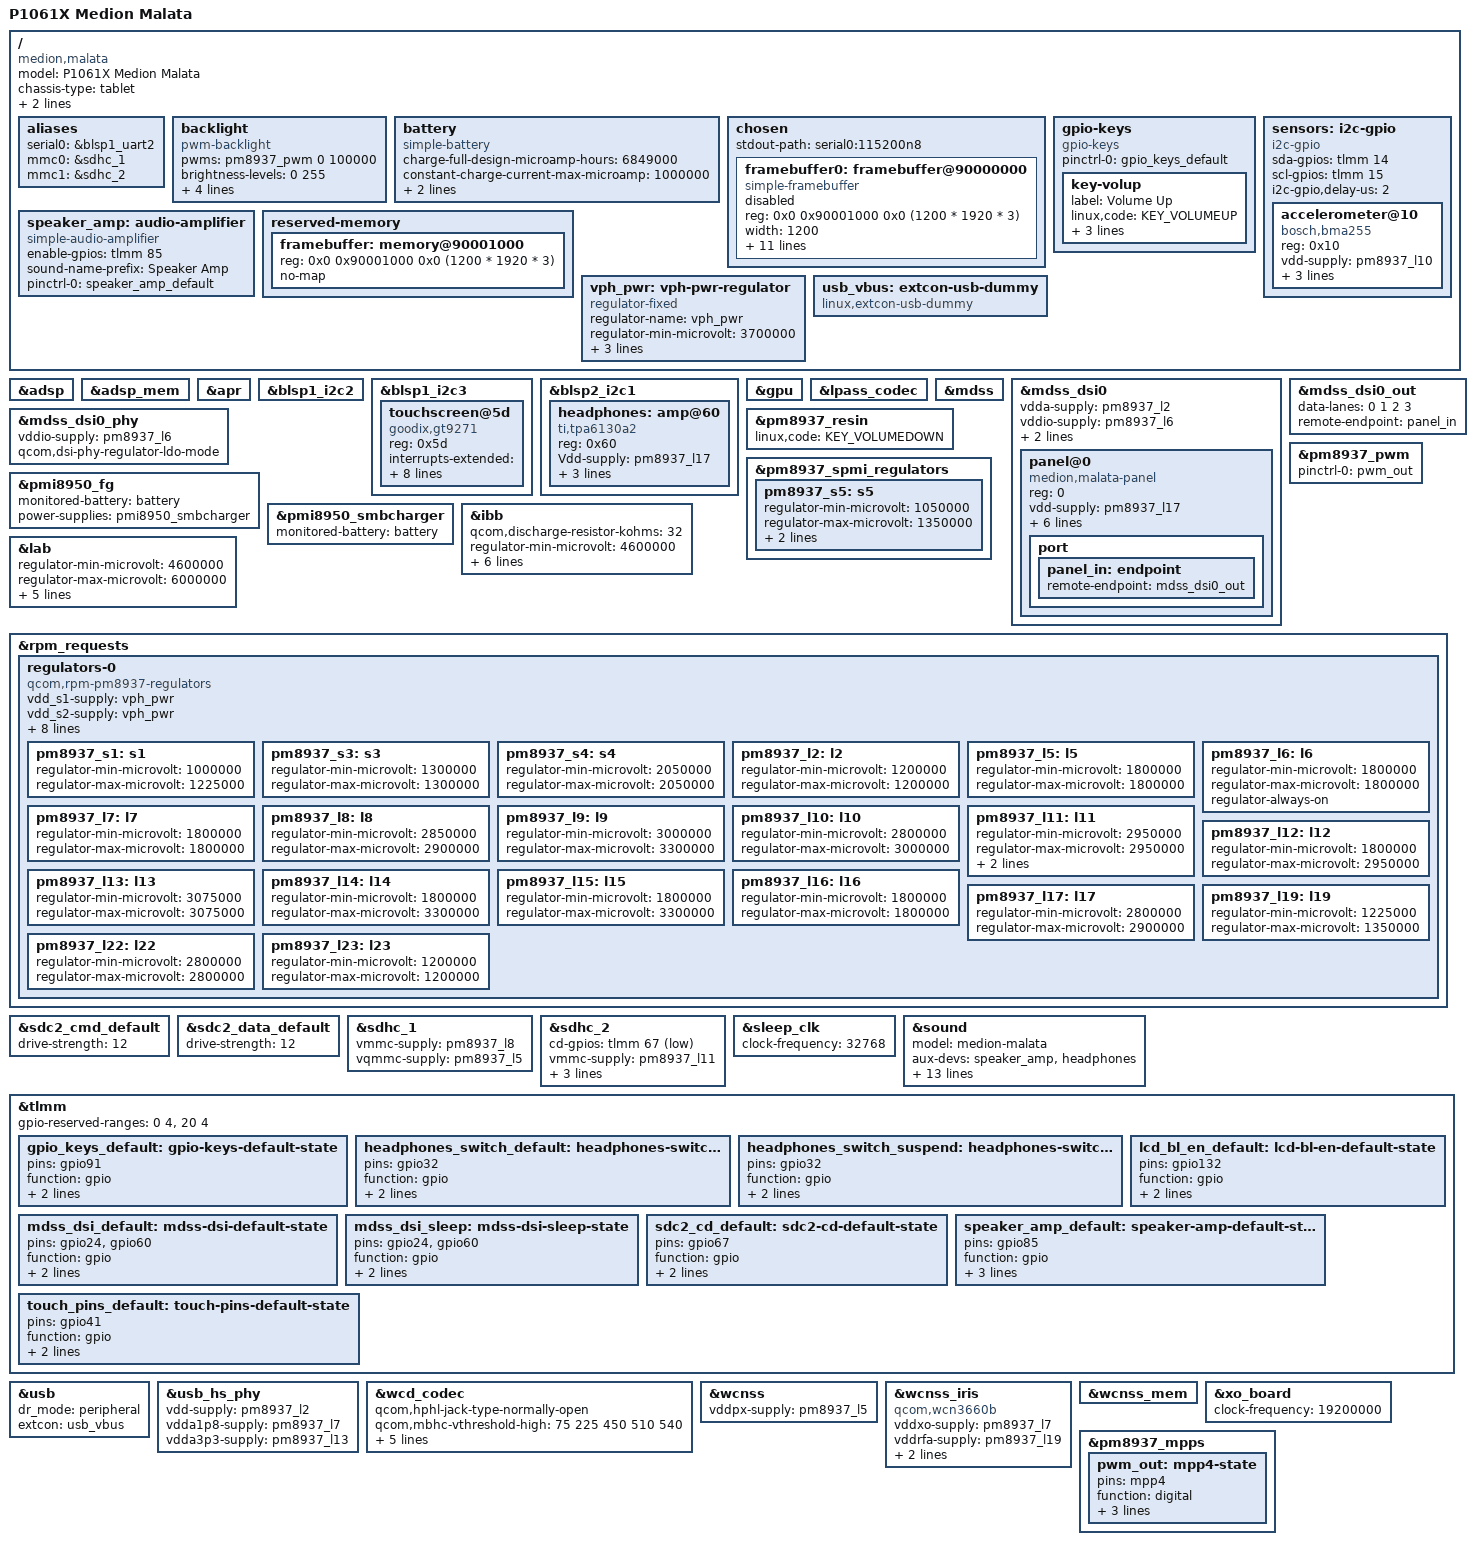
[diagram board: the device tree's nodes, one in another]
// SPDX-License-Identifier: BSD-3-Clause

/dts-v1/;

#include <dt-bindings/arm/qcom,ids.h>
#include <dt-bindings/gpio/gpio.h>
#include <dt-bindings/interrupt-controller/irq.h>
#include <dt-bindings/leds/common.h>
#include <dt-bindings/pinctrl/qcom,pmic-mpp.h>

#include "msm8937.dtsi"
#include "pm8937.dtsi"
#include "pmi8950.dtsi"
#include "msm8937-qdsp6.dtsi"

/ {
	model = "P1061X Medion Malata";
	compatible = "medion,malata", "qcom,msm8937";
	chassis-type = "tablet";

	qcom,msm-id = <QCOM_ID_MSM8937 0x0>;
	qcom,board-id = <QCOM_BOARD_ID_QRD 0x00>;

	aliases {
		serial0 = &blsp1_uart2;
		mmc0 = &sdhc_1;
		mmc1 = &sdhc_2;
	};

	backlight: backlight {
		compatible = "pwm-backlight";
		pwms = <&pm8937_pwm 0 100000>;

		brightness-levels = <0 255>;
		num-interpolated-steps = <255>;
		default-brightness-level = <128>;
		enable-gpios = <&tlmm 132 GPIO_ACTIVE_HIGH>;

		pinctrl-0 = <&lcd_bl_en_default>;
		pinctrl-names = "default";
	};

	battery: battery {
		compatible = "simple-battery";
 //TODO noch nicht komplett
		charge-full-design-microamp-hours = <6849000>;
		constant-charge-current-max-microamp = <1000000>;
		voltage-min-design-microvolt = <3400000>;
		voltage-max-design-microvolt = <4300000>;
	};

	chosen {
		#address-cells = <2>;
		#size-cells = <2>;
		ranges;
		stdout-path = "serial0:115200n8";
		//stdout-path = "framebuffer0";

		framebuffer0: framebuffer@90000000 {
			compatible = "simple-framebuffer";
			reg = <0x0 0x90001000 0x0 (1200 * 1920 * 3)>;
			width = <1200>;
			height = <1920>;
			stride = <(1200 * 3)>;
			format = "r8g8b8";

			clocks = <&gcc GCC_MDSS_AHB_CLK>,
				 <&gcc GCC_MDSS_AXI_CLK>,
				 <&gcc GCC_MDSS_VSYNC_CLK>,
				 <&gcc GCC_MDSS_MDP_CLK>,
				 <&gcc GCC_MDSS_BYTE0_CLK>,
				 <&gcc GCC_MDSS_PCLK0_CLK>,
				 <&gcc GCC_MDSS_ESC0_CLK>;
			power-domains = <&gcc MDSS_GDSC>;
			status = "disabled";
		};
	};

	gpio-keys {
		compatible = "gpio-keys";

		pinctrl-0 = <&gpio_keys_default>;
		pinctrl-names = "default";

		key-volup {
			label = "Volume Up";
			linux,code = <KEY_VOLUMEUP>;
			gpios = <&tlmm 91 GPIO_ACTIVE_LOW>,<&tlmm 127 GPIO_ACTIVE_LOW>,<&tlmm 128 GPIO_ACTIVE_LOW> ;
			debounce-interval = <15>;
		};
	};

	sensors: i2c-gpio {
		// i2c4 is protected, bitbanging
		compatible = "i2c-gpio";
		sda-gpios = <&tlmm 14 (GPIO_ACTIVE_HIGH|GPIO_OPEN_DRAIN)>;
		scl-gpios = <&tlmm 15 (GPIO_ACTIVE_HIGH|GPIO_OPEN_DRAIN)>;
		i2c-gpio,delay-us = <2>;        /* ~100 kHz */
		#address-cells = <1>;
		#size-cells = <0>;

		accelerometer@10 {
			compatible = "bosch,bma255";
			reg = <0x10>;

			vdd-supply = <&pm8937_l10>;
			vddio-supply = <&pm8937_l6>;

			interrupts-extended = <&tlmm 42 IRQ_TYPE_EDGE_RISING>;

			/*mount-matrix =	"0", "-1", "0",
					"1", "0", "0",
					"0", "0", "1";*/
		};
	};

	speaker_amp: audio-amplifier {
		compatible = "simple-audio-amplifier";
		enable-gpios = <&tlmm 85 GPIO_ACTIVE_HIGH>;
		sound-name-prefix = "Speaker Amp";
		pinctrl-0 = <&speaker_amp_default>;
		pinctrl-names = "default";
	};

	reserved-memory {
		framebuffer: memory@90001000 {
			//reg = <0x00 0x90001000 0x00 0x1400000>;
			reg = <0x0 0x90001000 0x0 (1200 * 1920 * 3)>;
			no-map;
		};

	/*	ramoops: ramoops@9ff00000 {
			compatible = "ramoops";
			reg = <0 0x9ff00000 0 0x100000>;

			record-size = <0x1000>;
			console-size = <0x40000>;
			ftrace-size = <0x1000>;
			pmsg-size = <0x20000>;
		};*/
	};

	vph_pwr: vph-pwr-regulator {
		compatible = "regulator-fixed";
		regulator-name = "vph_pwr";
		regulator-min-microvolt = <3700000>;
		regulator-max-microvolt = <3700000>;
		regulator-always-on;
		regulator-boot-on;
	};

	usb_vbus: extcon-usb-dummy {
		compatible = "linux,extcon-usb-dummy";
	};

	/*
	 * Until we hook up type-c detection, we
	 * have to stick with this. But it works.
	 
	usb_id: usb-id {
		compatible = "linux,extcon-usb-gpio";
		id-gpios = <&tlmm 97 GPIO_ACTIVE_HIGH>;
		pinctrl-names = "default";
		pinctrl-0 = <&usb_id_default>;
	};*/
};

&adsp {
	status = "okay";
};

&adsp_mem {
	status = "okay";
};

&apr {
	status = "okay";
};

&blsp1_i2c2 {
	status = "okay";

//TODO get it work
/*	typec_pd: usb-pd@3d {
		compatible = "pericom,pi3usb102", "gpio-sbu-mux";
		reg = <0x3d>;
*/
		/*interrupt-parent = <&tlmm>;
		interrupts = <97 IRQ_TYPE_LEVEL_LOW>;
		interrupt-names = "irq";*/

/*		pinctrl-names = "default";
		pinctrl-0 = <&pinctrl_typec>;
		vcc-supply = <&pm8937_l5>;
		select-gpios = <&tlmm  97 GPIO_ACTIVE_HIGH>;
		enable-gpios = <&tlmm 131 GPIO_ACTIVE_LOW>;
		mode-switch;
		orientation-switch;

		typec_con: connector {
			compatible = "usb-c-connector";
			label = "USB-C";

			port {
				typec_ep: endpoint {
					remote-endpoint = <&otg_ep>;
				};
			};
		};
	};
*/

};

&blsp1_i2c3 {
	status = "okay";

	touchscreen@5d { //fertig
		compatible = "goodix,gt9271";
		reg = <0x5d>;

		interrupts-extended = <&tlmm 41 IRQ_TYPE_EDGE_FALLING>;
		irq-gpios = <&tlmm 41 GPIO_ACTIVE_HIGH>;
		reset-gpios = <&tlmm 40 GPIO_ACTIVE_HIGH>;
		AVDD28-supply = <&pm8937_l17>;
		VDDIO-supply = <&pm8937_l6>;

		pinctrl-names = "default";
		pinctrl-0 = <&touch_pins_default>;

		touchscreen-size-x = <1200>;
		touchscreen-size-y = <1920>;

	//	touchscreen-inverted-x = true;
	//	touchscreen-swapped-x-y = true;
	};
};

&blsp2_i2c1 {
	status = "okay";

	headphones: amp@60 {
		compatible = "ti,tpa6130a2";
		reg = <0x60>;
		Vdd-supply = <&pm8937_l17>;
		power-gpio = <&tlmm 32 GPIO_ACTIVE_HIGH>;

		pinctrl-0 = <&headphones_switch_default>;
		pinctrl-1 = <&headphones_switch_suspend>;
		pinctrl-names = "default","sleep";
		#sound-dai-cells = <0>;
	};
};

&gpu {
	status = "okay";
};

&lpass_codec{
	status = "okay";
};

&mdss {
	status = "okay";
};

&mdss_dsi0 {
	vdda-supply = <&pm8937_l2>;
	vddio-supply = <&pm8937_l6>;

	pinctrl-0 = <&mdss_dsi_default>;
	pinctrl-1 = <&mdss_dsi_sleep>;
	pinctrl-names = "default", "sleep";

	status = "okay";

	panel@0 {
		compatible = "medion,malata-panel";
		//compatible = "malata,gama-wuxga";
		reg = <0>;
		vdd-supply =<&pm8937_l17>;
		vddio-supply =<&pm8937_l6>;
		vsp-supply =<&lab>;
		vsn-supply =<&ibb>;

		//backlight-gpios = <&tlmm 132 GPIO_ACTIVE_LOW>;
		enable-gpios = <&tlmm 24 GPIO_ACTIVE_HIGH>;

		reset-gpios = <&tlmm 60 GPIO_ACTIVE_LOW>;

		backlight = <&backlight>; 

		port {
			panel_in: endpoint {
				remote-endpoint = <&mdss_dsi0_out>;
			};
		};
	};
};

&mdss_dsi0_out {
	data-lanes = <0 1 2 3>;
	remote-endpoint = <&panel_in>;
};

&mdss_dsi0_phy {
	vddio-supply = <&pm8937_l6>;
	qcom,dsi-phy-regulator-ldo-mode;

	status = "okay";
};

&pm8937_resin {
	linux,code = <KEY_VOLUMEDOWN>;
	status = "okay";
};

&pm8937_spmi_regulators {
	pm8937_s5: s5 {
		regulator-min-microvolt = <1050000>;
		regulator-max-microvolt = <1350000>;
		regulator-always-on;
		regulator-boot-on;
	};
};

&pmi8950_fg {
	monitored-battery = <&battery>;
	power-supplies = <&pmi8950_smbcharger>;
	status = "okay";
};

&pmi8950_smbcharger {
	monitored-battery = <&battery>;
	status = "okay";
};

&pm8937_pwm {
	status = "okay";
	pinctrl-names = "default";
	pinctrl-0 = <&pwm_out>;
};

&ibb {
	qcom,discharge-resistor-kohms = <32>;
	regulator-min-microvolt = <4600000>;
	regulator-max-microvolt = <6000000>;
	regulator-min-microamp = <0>;
	regulator-max-microamp = <800000>;
	regulator-over-current-protection;
	regulator-soft-start;
	regulator-pull-down;
};

&lab {
	regulator-min-microvolt = <4600000>;
	regulator-max-microvolt = <6000000>;
	regulator-min-microamp = <200000>;
	regulator-max-microamp = <200000>;
	regulator-over-current-protection;
	regulator-soft-start;
	regulator-pull-down;
};

&rpm_requests {
	regulators-0 {
		compatible = "qcom,rpm-pm8937-regulators";

		vdd_s1-supply = <&vph_pwr>;
		vdd_s2-supply = <&vph_pwr>;
		vdd_s3-supply = <&vph_pwr>;
		vdd_s4-supply = <&vph_pwr>;

		vdd_l1_l19-supply = <&pm8937_s3>;
		vdd_l2_l23-supply = <&pm8937_s3>;
		vdd_l3-supply = <&pm8937_s3>;
		vdd_l4_l5_l6_l7_l16-supply = <&pm8937_s4>;
		vdd_l8_l11_l12_l17_l22-supply = <&vph_pwr>;
		vdd_l9_l10_l13_l14_l15_l18-supply = <&vph_pwr>;

		pm8937_s1: s1 {
			regulator-min-microvolt = <1000000>;
			regulator-max-microvolt = <1225000>;
		};

		pm8937_s3: s3 {
			regulator-min-microvolt = <1300000>;
			regulator-max-microvolt = <1300000>;
		};

		pm8937_s4: s4 {
			regulator-min-microvolt = <2050000>;
			regulator-max-microvolt = <2050000>;
		};

		pm8937_l2: l2 {
			regulator-min-microvolt = <1200000>;
			regulator-max-microvolt = <1200000>;
		};

		pm8937_l5: l5 {
			regulator-min-microvolt = <1800000>;
			regulator-max-microvolt = <1800000>;
		};

		pm8937_l6: l6 {
			regulator-min-microvolt = <1800000>;
			regulator-max-microvolt = <1800000>;
			regulator-always-on;
		};

		pm8937_l7: l7 {
			regulator-min-microvolt = <1800000>;
			regulator-max-microvolt = <1800000>;
		};

		pm8937_l8: l8 {
			regulator-min-microvolt = <2850000>;
			regulator-max-microvolt = <2900000>;
		};

		pm8937_l9: l9 {
			regulator-min-microvolt = <3000000>;
			regulator-max-microvolt = <3300000>;
		};

		pm8937_l10: l10 {
			regulator-min-microvolt = <2800000>;
			regulator-max-microvolt = <3000000>;
		};

		pm8937_l11: l11 {
			regulator-min-microvolt = <2950000>;
			regulator-max-microvolt = <2950000>;
			regulator-allow-set-load;
			regulator-system-load = <200000>;
		};

		pm8937_l12: l12 {
			regulator-min-microvolt = <1800000>;
			regulator-max-microvolt = <2950000>;
		};

		pm8937_l13: l13 {
			regulator-min-microvolt = <3075000>;
			regulator-max-microvolt = <3075000>;
		};

		pm8937_l14: l14 {
			regulator-min-microvolt = <1800000>;
			regulator-max-microvolt = <3300000>;
		};

		pm8937_l15: l15 {
			regulator-min-microvolt = <1800000>;
			regulator-max-microvolt = <3300000>;
		};

		pm8937_l16: l16 {
			regulator-min-microvolt = <1800000>;
			regulator-max-microvolt = <1800000>;
		};

		pm8937_l17: l17 {
			regulator-min-microvolt = <2800000>;
			regulator-max-microvolt = <2900000>;
		};

		pm8937_l19: l19 {
			regulator-min-microvolt = <1225000>;
			regulator-max-microvolt = <1350000>;
		};

		pm8937_l22: l22 {
			regulator-min-microvolt = <2800000>;
			regulator-max-microvolt = <2800000>;
		};

		pm8937_l23: l23 {
			regulator-min-microvolt = <1200000>;
			regulator-max-microvolt = <1200000>;
		};
	};
};

&sdc2_cmd_default {
	drive-strength = <12>;
};

&sdc2_data_default {
	drive-strength = <12>;
};

&sdhc_1 {
	vmmc-supply = <&pm8937_l8>;
	vqmmc-supply = <&pm8937_l5>;
	status = "okay";
};

&sdhc_2 {
	cd-gpios = <&tlmm 67 GPIO_ACTIVE_LOW>;
	vmmc-supply = <&pm8937_l11>;
	vqmmc-supply = <&pm8937_l12>;
	pinctrl-0 = <&sdc2_default &sdc2_cd_default>;
	pinctrl-1 = <&sdc2_sleep &sdc2_cd_default>;
	pinctrl-names = "default", "sleep";
	status = "okay";
};

&sleep_clk {
	clock-frequency = <32768>;
};

&sound {
	model = "medion-malata";

	aux-devs = <&speaker_amp>, <&headphones>;
	widgets =
		"Speaker", "Headphone", "Headphone Jack";
	pin-switches = "Speaker","headphones";
	audio-routing =
		"Speaker", "Speaker Amp OUT",
		"Speaker Amp IN", "HPHR",
		"Headphone Jack", "HPLEFT",
		"Headphone Jack", "HPRIGHT",
		"LEFTIN", "HPL",
		"RIGHTIN", "HPR",
		"AMIC1", "MIC BIAS External1",
		"AMIC2", "MIC BIAS Internal2",
		"AMIC3", "MIC BIAS External1",
		"MM_DL1", "MultiMedia1 Playback",
		"MM_DL3", "MultiMedia3 Playback",
		"MM_DL4", "MultiMedia4 Playback",
		"MultiMedia2 Capture", "MM_UL2";

	status = "okay";
};
/*
&sound_dai_secondary {
	status = "okay";

	codec {
		sound-dai = <&headphones>;
	};
};*/

&tlmm {
	gpio-reserved-ranges = <0 4>, <20 4>;

	gpio_keys_default: gpio-keys-default-state {
		pins = "gpio91";
		function = "gpio";
		drive-strength = <2>;
		bias-pull-up;
	};

	headphones_switch_default: headphones-switch-default-state {
		pins = "gpio32";
		function = "gpio";
		drive-strength = <2>;
		output-high;
	};

	headphones_switch_suspend: headphones-switch-suspend-state {
		pins = "gpio32";
		function = "gpio";
		drive-strength = <2>;
		output-low;
	};

	lcd_bl_en_default: lcd-bl-en-default-state {
		pins = "gpio132";
		function = "gpio";
		drive-strength = <2>;
		bias-disable;
	};

	mdss_dsi_default: mdss-dsi-default-state {
		pins = "gpio24","gpio60";
		function = "gpio";
		drive-strength = <8>;
		bias-pull-up;
	};

	mdss_dsi_sleep: mdss-dsi-sleep-state {
		pins = "gpio24","gpio60";
		function = "gpio";
		drive-strength = <8>;
		bias-pull-up;
	};

	sdc2_cd_default: sdc2-cd-default-state {
		pins = "gpio67";
		function = "gpio";
		drive-strength = <2>;
		bias-disable;
	};

	speaker_amp_default: speaker-amp-default-state {
		pins = "gpio85";
		function = "gpio";
		drive-strength = <2>;
		bias-disable;
		output-low;
	};

	touch_pins_default: touch-pins-default-state {
		pins = "gpio41";
		function = "gpio";
		drive-strength = <2>;
		bias-disable;
	};

	/*pinctrl_otg_default: otg-default-state {
		function = "gpio";
		pins = "gpio97";
		output-high;
	};

	pinctrl_otg_device: otg-device-state {
		function = "gpio";
		pins = "gpio97";
		output-low;
	};

	pinctrl_otg_host: otg-host-state {
		function = "gpio";
		pins = "gpio97";
		output-low;
	};

	pinctrl_typec: pinctrl-typec-state {
		function = "gpio";
		pins = "gpio131";
		bias-pull-up;
	};*/
};

&usb {
	dr_mode = "peripheral";
	extcon = <&usb_vbus>;
	status = "okay";
};

&usb_hs_phy {
	vdd-supply = <&pm8937_l2>;
	vdda1p8-supply = <&pm8937_l7>;
	vdda3p3-supply = <&pm8937_l13>;
	status = "okay";
};

&wcd_codec {
	qcom,hphl-jack-type-normally-open;
	qcom,mbhc-vthreshold-high = <75 225 450 510 540>;
	qcom,mbhc-vthreshold-low = <25 200 325 500 530>;
	qcom,micbias1-ext-cap;

	vdd-cdc-io-supply = <&pm8937_l5>;
	vdd-cdc-tx-rx-cx-supply = <&pm8937_s4>;
	vdd-micbias-supply = <&pm8937_l13>;
	status = "okay";
};

&wcnss {
	vddpx-supply = <&pm8937_l5>;
	status = "okay";
};

&wcnss_iris { //fertig
	compatible = "qcom,wcn3660b";
	vddxo-supply = <&pm8937_l7>;
	vddrfa-supply = <&pm8937_l19>;
	vddpa-supply = <&pm8937_l9>;
	vdddig-supply = <&pm8937_l5>;
};

&wcnss_mem {
	status = "okay";
};

&xo_board {
	clock-frequency = <19200000>;
};

&pm8937_mpps {
	pwm_out: mpp4-state {
		pins = "mpp4";
		function = "digital";
		power-source = <PM8916_MPP_L5>;
		output-low;
		qcom,dtest = <1>;
	};
};
